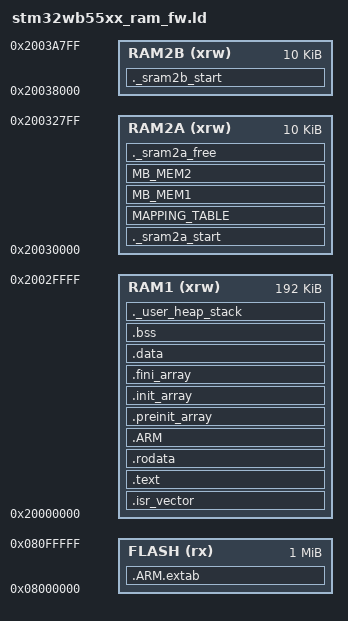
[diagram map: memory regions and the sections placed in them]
/**
*****************************************************************************
**
**  File        : stm32wb55xx_flash_cm4.ld
**
**  Abstract    : System Workbench Minimal System calls file
**
** 		          For more information about which c-functions
**                need which of these lowlevel functions
**                please consult the Newlib libc-manual
**
**  Environment : System Workbench for MCU
**
**  Distribution: The file is distributed “as is,” without any warranty
**                of any kind.
**
*****************************************************************************
**
** <h2><center>&copy; COPYRIGHT(c) 2019 Ac6</center></h2>
**
** Redistribution and use in source and binary forms, with or without modification,
** are permitted provided that the following conditions are met:
**   1. Redistributions of source code must retain the above copyright notice,
**      this list of conditions and the following disclaimer.
**   2. Redistributions in binary form must reproduce the above copyright notice,
**      this list of conditions and the following disclaimer in the documentation
**      and/or other materials provided with the distribution.
**   3. Neither the name of Ac6 nor the names of its contributors
**      may be used to endorse or promote products derived from this software
**      without specific prior written permission.
**
** THIS SOFTWARE IS PROVIDED BY THE COPYRIGHT HOLDERS AND CONTRIBUTORS "AS IS"
** AND ANY EXPRESS OR IMPLIED WARRANTIES, INCLUDING, BUT NOT LIMITED TO, THE
** IMPLIED WARRANTIES OF MERCHANTABILITY AND FITNESS FOR A PARTICULAR PURPOSE ARE
** DISCLAIMED. IN NO EVENT SHALL THE COPYRIGHT HOLDER OR CONTRIBUTORS BE LIABLE
** FOR ANY DIRECT, INDIRECT, INCIDENTAL, SPECIAL, EXEMPLARY, OR CONSEQUENTIAL
** DAMAGES (INCLUDING, BUT NOT LIMITED TO, PROCUREMENT OF SUBSTITUTE GOODS OR
** SERVICES; LOSS OF USE, DATA, OR PROFITS; OR BUSINESS INTERRUPTION) HOWEVER
** CAUSED AND ON ANY THEORY OF LIABILITY, WHETHER IN CONTRACT, STRICT LIABILITY,
** OR TORT (INCLUDING NEGLIGENCE OR OTHERWISE) ARISING IN ANY WAY OUT OF THE USE
** OF THIS SOFTWARE, EVEN IF ADVISED OF THE POSSIBILITY OF SUCH DAMAGE.
**
*****************************************************************************
*/

/* Entry Point */
ENTRY(Reset_Handler)

/* Highest address of the user mode stack */
_estack = 0x20030000;    /* end of RAM */
/* Generate a link error if heap and stack don't fit into RAM */
_Min_Heap_Size = 0x400;      /* required amount of heap  */
_Min_Stack_Size = 0x1000; /* required amount of stack */

/* Specify the memory areas */
MEMORY
{
FLASH (rx)                 : ORIGIN = 0x08000000, LENGTH = 1024K
RAM1 (xrw)                 : ORIGIN = 0x20000000, LENGTH = 0x30000
RAM2A (xrw)                : ORIGIN = 0x20030000, LENGTH = 10K
RAM2B (xrw)                : ORIGIN = 0x20038000, LENGTH = 10K
}

/* Define output sections */
SECTIONS
{
  /* The startup code goes first into FLASH */
  .isr_vector :
  {
    . = ALIGN(4);
    KEEP(*(.isr_vector)) /* Startup code */
    . = ALIGN(4);
  } >RAM1

  /* The program code and other data goes into FLASH */
  .text :
  {
    . = ALIGN(4);
    *(.text)           /* .text sections (code) */
    *(.text*)          /* .text* sections (code) */
    *(.glue_7)         /* glue arm to thumb code */
    *(.glue_7t)        /* glue thumb to arm code */
    *(.eh_frame)

    KEEP (*(.init))
    KEEP (*(.fini))

    . = ALIGN(4);
    _etext = .;        /* define a global symbols at end of code */
  } >RAM1

  /* Constant data goes into FLASH */
  .rodata :
  {
    . = ALIGN(4);
    *(.rodata)         /* .rodata sections (constants, strings, etc.) */
    *(.rodata*)        /* .rodata* sections (constants, strings, etc.) */
    . = ALIGN(4);
  } >RAM1

  .ARM.extab   : { *(.ARM.extab* .gnu.linkonce.armextab.*) } >FLASH
  .ARM : {
    __exidx_start = .;
    *(.ARM.exidx*)
    __exidx_end = .;
  } >RAM1

  .preinit_array     :
  {
    PROVIDE_HIDDEN (__preinit_array_start = .);
    KEEP (*(.preinit_array*))
    PROVIDE_HIDDEN (__preinit_array_end = .);
  } >RAM1
  .init_array :
  {
    PROVIDE_HIDDEN (__init_array_start = .);
    KEEP (*(SORT(.init_array.*)))
    KEEP (*(.init_array*))
    PROVIDE_HIDDEN (__init_array_end = .);
  } >RAM1
  .fini_array :
  {
    PROVIDE_HIDDEN (__fini_array_start = .);
    KEEP (*(SORT(.fini_array.*)))
    KEEP (*(.fini_array*))
    PROVIDE_HIDDEN (__fini_array_end = .);
  } >RAM1

  /* used by the startup to initialize data */
  _sidata = LOADADDR(.data);

  /* Initialized data sections goes into RAM, load LMA copy after code */
  .data : 
  {
    . = ALIGN(4);
    _sdata = .;        /* create a global symbol at data start */
    *(.data)           /* .data sections */
    *(.data*)          /* .data* sections */

    . = ALIGN(4);
    _edata = .;        /* define a global symbol at data end */
  } >RAM1 AT> RAM1

  
  /* Uninitialized data section */
  . = ALIGN(4);
  .bss :
  {
    /* This is used by the startup in order to initialize the .bss secion */
    _sbss = .;         /* define a global symbol at bss start */
    __bss_start__ = _sbss;
    *(.bss)
    *(.bss*)
    *(COMMON)

    . = ALIGN(4);
    _ebss = .;         /* define a global symbol at bss end */
    __bss_end__ = _ebss;
  } >RAM1

  /* User_heap_stack section, used to check that there is enough RAM left */
  ._user_heap_stack(DSECT) :
  {
    . = ALIGN(8);
    __heap_start__ = .;
    . = ORIGIN(RAM1) + LENGTH(RAM1) - _Min_Stack_Size;
    __heap_end__ = .;
    . = . + _Min_Stack_Size;
    . = ALIGN(8);
  } >RAM1

  /* Free Flash space, that can be used for internal storage */
  /*.free_flash(DSECT):
  {
    __free_flash_start__ = .;
    . = ORIGIN(FLASH) + LENGTH(FLASH);
  } >FLASH*/

  /* Remove information from the standard libraries */
  /DISCARD/ :
  {
    libc.a ( * )
    libm.a ( * )
    libgcc.a ( * )
  }

  .ARM.attributes 0       : { *(.ARM.attributes) }
  ._sram2a_start : { . = ALIGN(4); __sram2a_start__ = .; } >RAM2A
   MAPPING_TABLE (NOLOAD) : { *(MAPPING_TABLE) } >RAM2A
   MB_MEM1 (NOLOAD)       : { *(MB_MEM1) } >RAM2A
   MB_MEM2 (NOLOAD)       : { _sMB_MEM2 = . ; *(MB_MEM2) ; _eMB_MEM2 = . ; } >RAM2A
  ._sram2a_free : { . = ALIGN(4); __sram2a_free__ = .; } >RAM2A
  ._sram2b_start : { . = ALIGN(4); __sram2b_start__ = .; } >RAM2B
}


